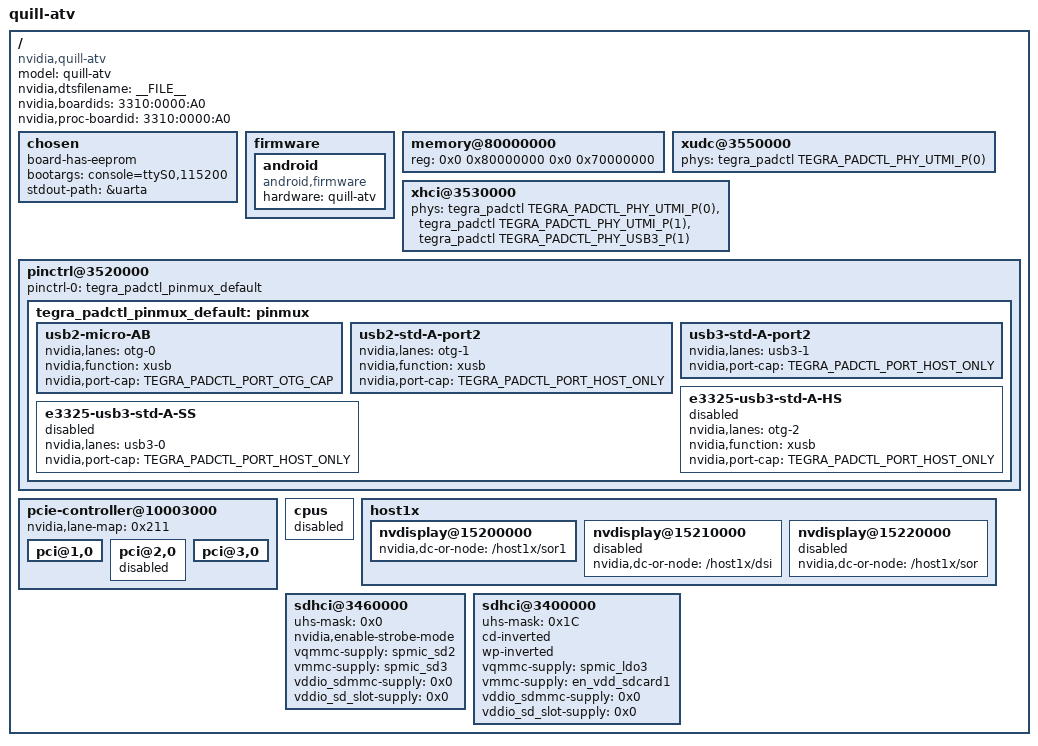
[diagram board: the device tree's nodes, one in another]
/*

 * tegra186-priv-quill-atv-p3310-1000-a00-00-base.dts Quill A00 Board
 *
 * Copyright (c) 2016, NVIDIA CORPORATION.  All rights reserved.
 *
 * This program is free software; you can redistribute it and/or modify
 * it under the terms of the GNU General Public License as published by
 * the Free Software Foundation; version 2 of the License.
 *
 * This program is distributed in the hope that it will be useful, but WITHOUT
 * ANY WARRANTY; without even the implied warranty of MERCHANTABILITY or
 * FITNESS FOR A PARTICULAR PURPOSE.  See the GNU General Public License for
 * more details.
 */

#include "tegra186-platforms/tegra186-quill-common-p3310-1000-a00.dtsi"
#include "tegra186-platforms/tegra186-quill-power-tree-p3310-1000-a00-00.dtsi"

/* comms dtsi file should be included after gpio dtsi file */
#include "tegra186-platforms/tegra186-quill-comms.dtsi"
#include "tegra186-plugin-manager/tegra186-quill-p3310-1000-a00-plugin-manager.dtsi"
#include "tegra186-prod/tegra186-priv-quill-p3310-1000-a00-prod.dtsi"

/ {
	model = "quill-atv";
	compatible = "nvidia,quill-atv", "nvidia,tegra186";

	nvidia,dtsfilename = __FILE__;
	nvidia,boardids = "3310:0000:A0";
	nvidia,proc-boardid = "3310:0000:A0";

	chosen {
		board-has-eeprom;
		bootargs ="console=ttyS0,115200";
		stdout-path = &uarta;
	};

	firmware {
		android {
			compatible = "android,firmware";
			hardware = "quill-atv";
		};
	};

	memory@80000000 {
		device_type = "memory";
		reg = <0x0 0x80000000 0x0 0x70000000>;
	};

	xudc@3550000 {
		status = "okay";
		phys = <&tegra_padctl TEGRA_PADCTL_PHY_UTMI_P(0)>;
		phy-names = "usb2";
	};

	xhci@3530000 {
		status = "okay";
		phys = <&tegra_padctl TEGRA_PADCTL_PHY_UTMI_P(0)>,
		 <&tegra_padctl TEGRA_PADCTL_PHY_UTMI_P(1)>,
		 <&tegra_padctl TEGRA_PADCTL_PHY_USB3_P(1)>;
		phy-names = "utmi-0", "utmi-1", "usb3-1";
	};

	pinctrl@3520000 {
		status = "okay";
		pinctrl-0 = <&tegra_padctl_pinmux_default>;
		pinctrl-names = "default";
tegra_padctl_pinmux_default: pinmux {
			  /* Quill does not support usb3-micro AB */
			  usb2-micro-AB {
				  nvidia,lanes = "otg-0";
				  nvidia,function = "xusb";
				  nvidia,port-cap = <TEGRA_PADCTL_PORT_OTG_CAP>;
			  };
			  usb2-std-A-port2 {
				  nvidia,lanes = "otg-1";
				  nvidia,function = "xusb";
				  nvidia,port-cap = <TEGRA_PADCTL_PORT_HOST_ONLY>;
			  };
			  usb3-std-A-port2 {
				  nvidia,lanes = "usb3-1";
				  nvidia,port-cap = <TEGRA_PADCTL_PORT_HOST_ONLY>;
			  };

			  e3325-usb3-std-A-HS {
				  nvidia,lanes = "otg-2";
				  nvidia,function = "xusb";
				  nvidia,port-cap = <TEGRA_PADCTL_PORT_HOST_ONLY>;
				  status = "disabled";
			  };

			  e3325-usb3-std-A-SS {
				  nvidia,lanes = "usb3-0";
				  nvidia,port-cap = <TEGRA_PADCTL_PORT_HOST_ONLY>;
				  status = "disabled";
			  };
		  };
	};

	pcie-controller@10003000 {
		nvidia,lane-map = <0x211>;
		status = "okay";
		pci@1,0 {
			status = "okay";
		};
		pci@2,0 {
			status = "disabled";
		};
		pci@3,0 {
			status = "okay";
		};
	};

	cpus {
		status = "disabled";
	};

	host1x {
		nvdisplay@15200000 {
			status = "okay";
			nvidia,dc-or-node = "/host1x/sor1";
		};
		nvdisplay@15210000 {
			status = "disabled";
			nvidia,dc-or-node = "/host1x/dsi";
		};
		nvdisplay@15220000 {
			status = "disabled";
			nvidia,dc-or-node = "/host1x/sor";
		};
	};

	sdhci@3460000 {
		uhs-mask = <0x0>; /*enable HS400 mode*/
		nvidia,enable-strobe-mode;
		status = "okay";
		vqmmc-supply = <&spmic_sd2>;
		vmmc-supply = <&spmic_sd3>;
		vddio_sdmmc-supply = <0x0>;
		vddio_sd_slot-supply = <0x0>;
	};
	sdhci@3400000 {
		uhs-mask = <0x1C>;
		cd-inverted;
		wp-inverted;
		status = "okay";
		vqmmc-supply = <&spmic_ldo3>;
		vmmc-supply = <&en_vdd_sdcard1>;
		vddio_sdmmc-supply = <0x0>;
		vddio_sd_slot-supply = <0x0>;
	};
};
